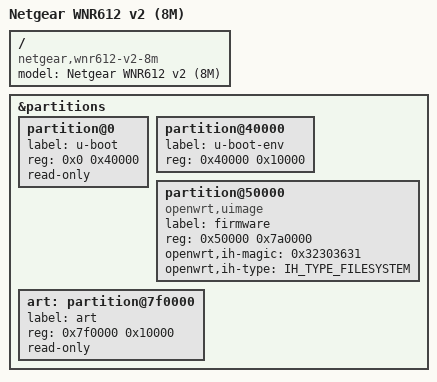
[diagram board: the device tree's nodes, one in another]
// SPDX-License-Identifier: GPL-2.0-or-later OR MIT

#include "ar7240_netgear_wnr612-v2.dtsi"

/ {
	compatible = "netgear,wnr612-v2-8m", "qca,ar7240";
	model = "Netgear WNR612 v2 (8M)";
};

&partitions {
	partition@0 {
		label = "u-boot";
		reg = <0x0 0x40000>;
		read-only;
	};

	partition@40000 {
		label = "u-boot-env";
		reg = <0x40000 0x10000>;
	};

	partition@50000 {
		label = "firmware";
		reg = <0x50000 0x7a0000>;
		compatible = "openwrt,uimage", "denx,uimage";
		openwrt,ih-magic = <0x32303631>;
		openwrt,ih-type = <IH_TYPE_FILESYSTEM>;
	};

	art: partition@7f0000 {
		label = "art";
		reg = <0x7f0000 0x10000>;
		read-only;
	};
};
